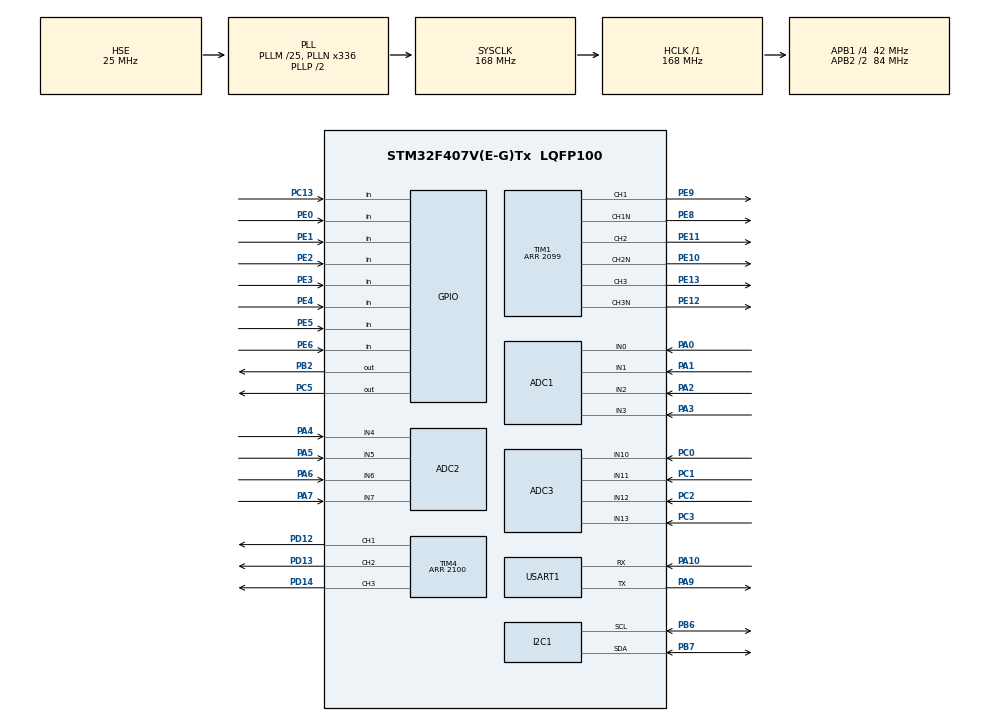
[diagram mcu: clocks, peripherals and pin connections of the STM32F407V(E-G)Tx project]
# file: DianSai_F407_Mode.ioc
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ADC1.Channel-0\#ChannelRegularConversion=ADC_CHANNEL_0
ADC1.NbrOfConversionFlag=1
ADC1.Rank-0\#ChannelRegularConversion=1
ADC1.SamplingTime-0\#ChannelRegularConversion=ADC_SAMPLETIME_3CYCLES
ADC1.master=1
ADC2.Channel-0\#ChannelRegularConversion=ADC_CHANNEL_4
ADC2.NbrOfConversionFlag=1
ADC2.Rank-0\#ChannelRegularConversion=1
ADC2.SamplingTime-0\#ChannelRegularConversion=ADC_SAMPLETIME_3CYCLES
ADC3.Channel-0\#ChannelRegularConversion=ADC_CHANNEL_13
ADC3.NbrOfConversionFlag=1
ADC3.Rank-0\#ChannelRegularConversion=1
ADC3.SamplingTime-0\#ChannelRegularConversion=ADC_SAMPLETIME_3CYCLES
Dma.Request0=USART1_RX
Dma.USART1_RX.0.Direction=DMA_PERIPH_TO_MEMORY
Dma.USART1_RX.0.FIFOMode=DMA_FIFOMODE_DISABLE
Dma.USART1_RX.0.Instance=DMA2_Stream2
Dma.USART1_RX.0.MemDataAlignment=DMA_MDATAALIGN_BYTE
Dma.USART1_RX.0.MemInc=DMA_MINC_ENABLE
Dma.USART1_RX.0.Mode=DMA_NORMAL
Dma.USART1_RX.0.PeriphDataAlignment=DMA_PDATAALIGN_BYTE
Dma.USART1_RX.0.PeriphInc=DMA_PINC_DISABLE
Dma.USART1_RX.0.Priority=DMA_PRIORITY_HIGH
I2C1.I2C_Mode=I2C_Fast
Mcu.Family=STM32F4
Mcu.Name=STM32F407V(E-G)Tx
Mcu.Package=LQFP100
NVIC.DMA2_Stream2_IRQn=true\:0\:0\:false\:false\:true\:false\:true\:true
NVIC.PriorityGroup=NVIC_PRIORITYGROUP_4
NVIC.TIM1_UP_TIM10_IRQn=true\:0\:0\:false\:false\:true\:true\:true\:true
NVIC.TIM4_IRQn=true\:0\:0\:false\:false\:true\:true\:true\:true
NVIC.USART1_IRQn=true\:0\:0\:false\:false\:true\:true\:true\:true
PA0-WKUP.Signal=ADCx_IN0
PA1.Signal=ADCx_IN1
PA10.Mode=Asynchronous
PA10.Signal=USART1_RX
PA2.Signal=ADCx_IN2
PA3.Signal=ADCx_IN3
PA4.Signal=ADCx_IN4
PA5.Signal=ADCx_IN5
PA6.Signal=ADCx_IN6
PA7.Signal=ADCx_IN7
PA9.Mode=Asynchronous
PA9.Signal=USART1_TX
PB2.GPIO_PuPd=GPIO_NOPULL
PB2.PinState=GPIO_PIN_SET
PB2.Signal=GPIO_Output
PB6.Mode=I2C
PB6.Signal=I2C1_SCL
PB7.Mode=I2C
PB7.Signal=I2C1_SDA
PC0.Signal=ADCx_IN10
PC1.Signal=ADCx_IN11
PC13-ANTI_TAMP.GPIO_Mode=GPIO_MODE_INPUT
PC13-ANTI_TAMP.GPIO_PuPd=GPIO_PULLUP
PC13-ANTI_TAMP.Signal=GPIO_Input
PC2.Signal=ADCx_IN12
PC3.Signal=ADCx_IN13
PC5.GPIO_ModeDefaultOutputPP=GPIO_MODE_OUTPUT_PP
PC5.GPIO_PuPd=GPIO_NOPULL
PC5.PinState=GPIO_PIN_SET
PC5.Signal=GPIO_Output
PD0.Signal=CAN1_RX
PD1.Signal=CAN1_TX
PD12.Signal=S_TIM4_CH1
PD13.Signal=S_TIM4_CH2
PD14.Signal=S_TIM4_CH3
PD15.Signal=S_TIM4_CH4
PE0.GPIO_Mode=GPIO_MODE_INPUT
PE0.GPIO_PuPd=GPIO_PULLUP
PE0.Signal=GPIO_Input
PE1.GPIO_Mode=GPIO_MODE_INPUT
PE1.GPIO_PuPd=GPIO_PULLUP
PE1.Signal=GPIO_Input
PE10.Mode=PWM Generation2 CH2 CH2N
PE10.Signal=TIM1_CH2N
PE11.Signal=S_TIM1_CH2
PE12.Mode=PWM Generation3 CH3 CH3N
PE12.Signal=TIM1_CH3N
PE13.Signal=S_TIM1_CH3
PE2.GPIO_Mode=GPIO_MODE_INPUT
PE2.GPIO_PuPd=GPIO_PULLUP
PE2.Signal=GPIO_Input
PE3.GPIO_Mode=GPIO_MODE_INPUT
PE3.GPIO_PuPd=GPIO_PULLUP
PE3.Signal=GPIO_Input
PE4.GPIO_Mode=GPIO_MODE_INPUT
PE4.GPIO_PuPd=GPIO_PULLUP
PE4.Signal=GPIO_Input
PE5.GPIO_Mode=GPIO_MODE_INPUT
PE5.GPIO_PuPd=GPIO_PULLUP
PE5.Signal=GPIO_Input
PE6.GPIO_Mode=GPIO_MODE_INPUT
PE6.GPIO_PuPd=GPIO_PULLUP
PE6.Signal=GPIO_Input
PE8.Mode=PWM Generation1 CH1 CH1N
PE8.Signal=TIM1_CH1N
PE9.Signal=S_TIM1_CH1
PH0-OSC_IN.Mode=HSE-External-Oscillator
PH0-OSC_IN.Signal=RCC_OSC_IN
PH1-OSC_OUT.Mode=HSE-External-Oscillator
PH1-OSC_OUT.Signal=RCC_OSC_OUT
ProjectManager.HeapSize=0x200
ProjectManager.StackSize=0x400
ProjectManager.TargetToolchain=MDK-ARM V5.32
RCC.48MHZClocksFreq_Value=84000000
RCC.AHBFreq_Value=168000000
RCC.APB1CLKDivider=RCC_HCLK_DIV4
RCC.APB1Freq_Value=42000000
RCC.APB1TimFreq_Value=84000000
RCC.APB2CLKDivider=RCC_HCLK_DIV2
RCC.APB2Freq_Value=84000000
RCC.APB2TimFreq_Value=168000000
RCC.CortexFreq_Value=168000000
RCC.HCLKFreq_Value=168000000
RCC.HSE_VALUE=25000000
RCC.HSI_VALUE=16000000
RCC.LSE_VALUE=32768
RCC.PLLM=25
RCC.PLLN=336
RCC.PLLSourceVirtual=RCC_PLLSOURCE_HSE
RCC.SYSCLKFreq_VALUE=168000000
RCC.SYSCLKSource=RCC_SYSCLKSOURCE_PLLCLK
RCC.VCOOutputFreq_Value=336000000
SH.ADCx_IN0.0=ADC1_IN0,IN0
SH.ADCx_IN1.0=ADC1_IN1,IN1
SH.ADCx_IN10.0=ADC3_IN10,IN10
SH.ADCx_IN11.0=ADC3_IN11,IN11
SH.ADCx_IN12.0=ADC3_IN12,IN12
SH.ADCx_IN13.0=ADC3_IN13,IN13
SH.ADCx_IN2.0=ADC1_IN2,IN2
SH.ADCx_IN3.0=ADC1_IN3,IN3
SH.ADCx_IN4.0=ADC2_IN4,IN4
SH.ADCx_IN5.0=ADC2_IN5,IN5
SH.ADCx_IN6.0=ADC2_IN6,IN6
SH.ADCx_IN7.0=ADC2_IN7,IN7
SH.S_TIM1_CH1.0=TIM1_CH1,PWM Generation1 CH1 CH1N
SH.S_TIM1_CH2.0=TIM1_CH2,PWM Generation2 CH2 CH2N
SH.S_TIM1_CH3.0=TIM1_CH3,PWM Generation3 CH3 CH3N
SH.S_TIM4_CH1.0=TIM4_CH1,PWM Generation1 CH1
SH.S_TIM4_CH2.0=TIM4_CH2,PWM Generation2 CH2
SH.S_TIM4_CH3.0=TIM4_CH3,PWM Generation3 CH3
SH.S_TIM4_CH4.0=TIM4_CH4
TIM1.AutoReloadPreload=TIM_AUTORELOAD_PRELOAD_ENABLE
TIM1.AutomaticOutput=TIM_AUTOMATICOUTPUT_ENABLE
TIM1.Channel-PWM\ Generation1\ CH1\ CH1N=TIM_CHANNEL_1
TIM1.Channel-PWM\ Generation2\ CH2\ CH2N=TIM_CHANNEL_2
TIM1.Channel-PWM\ Generation3\ CH3\ CH3N=TIM_CHANNEL_3
TIM1.CounterMode=TIM_COUNTERMODE_CENTERALIGNED1
TIM1.Period=2099
TIM4.AutoReloadPreload=TIM_AUTORELOAD_PRELOAD_ENABLE
TIM4.Channel-PWM\ Generation1\ CH1=TIM_CHANNEL_1
TIM4.Channel-PWM\ Generation2\ CH2=TIM_CHANNEL_2
TIM4.Channel-PWM\ Generation3\ CH3=TIM_CHANNEL_3
TIM4.CounterMode=TIM_COUNTERMODE_CENTERALIGNED1
TIM4.Period=2100
USART1.VirtualMode=VM_ASYNC
VP_TIM1_VS_ClockSourceINT.Mode=Internal
VP_TIM4_VS_ClockSourceINT.Mode=Internal
board=custom

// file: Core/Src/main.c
/* USER CODE BEGIN Header */
/**
  ******************************************************************************
  * @file           : main.c
  * @brief          : Main program body
  ******************************************************************************
  * @attention
  *
  * Copyright (c) 2026 STMicroelectronics.
  * All rights reserved.
  *
  * This software is licensed under terms that can be found in the LICENSE file
  * in the root directory of this software component.
  * If no LICENSE file comes with this software, it is provided AS-IS.
  *
  ******************************************************************************
  */
/* USER CODE END Header */
#include "main.h"
#include "adc.h"
#include "dma.h"
#include "i2c.h"
#include "tim.h"
#include "usart.h"
#include "gpio.h"

/* USER CODE BEGIN Includes */
#include "bsp_system.h"
/* USER CODE END Includes */

void SystemClock_Config(void);

int main(void)
{

  /* MCU Configuration--------------------------------------------------------*/

  /* Reset of all peripherals, Initializes the Flash interface and the Systick. */
  HAL_Init();

  /* Configure the system clock */
  SystemClock_Config();

  /* Initialize all configured peripherals */
  MX_GPIO_Init();
  MX_DMA_Init();
  MX_I2C1_Init();
  MX_USART1_UART_Init();
  MX_ADC1_Init();
  MX_ADC2_Init();
  MX_ADC3_Init();
  MX_TIM1_Init();
  MX_TIM4_Init();
  /* USER CODE BEGIN 2 */
  system_init();

  /* USER CODE END 2 */

  /* Infinite loop */
  while (1)
  {

    /* USER CODE BEGIN 3 */
		scheduler_run();
  }
  /* USER CODE END 3 */
}

void SystemClock_Config(void)
{
  RCC_OscInitTypeDef RCC_OscInitStruct = {0};
  RCC_ClkInitTypeDef RCC_ClkInitStruct = {0};

  /** Configure the main internal regulator output voltage
  */
  __HAL_RCC_PWR_CLK_ENABLE();
  __HAL_PWR_VOLTAGESCALING_CONFIG(PWR_REGULATOR_VOLTAGE_SCALE1);

  /** Initializes the RCC Oscillators according to the specified parameters
  * in the RCC_OscInitTypeDef structure.
  */
  RCC_OscInitStruct.OscillatorType = RCC_OSCILLATORTYPE_HSE;
  RCC_OscInitStruct.HSEState = RCC_HSE_ON;
  RCC_OscInitStruct.PLL.PLLState = RCC_PLL_ON;
  RCC_OscInitStruct.PLL.PLLSource = RCC_PLLSOURCE_HSE;
  RCC_OscInitStruct.PLL.PLLM = 25;
  RCC_OscInitStruct.PLL.PLLN = 336;
  RCC_OscInitStruct.PLL.PLLP = RCC_PLLP_DIV2;
  RCC_OscInitStruct.PLL.PLLQ = 4;
  if (HAL_RCC_OscConfig(&RCC_OscInitStruct) != HAL_OK)
  {
    Error_Handler();
  }

  /** Initializes the CPU, AHB and APB buses clocks
  */
  RCC_ClkInitStruct.ClockType = RCC_CLOCKTYPE_HCLK|RCC_CLOCKTYPE_SYSCLK
                              |RCC_CLOCKTYPE_PCLK1|RCC_CLOCKTYPE_PCLK2;
  RCC_ClkInitStruct.SYSCLKSource = RCC_SYSCLKSOURCE_PLLCLK;
  RCC_ClkInitStruct.AHBCLKDivider = RCC_SYSCLK_DIV1;
  RCC_ClkInitStruct.APB1CLKDivider = RCC_HCLK_DIV4;
  RCC_ClkInitStruct.APB2CLKDivider = RCC_HCLK_DIV2;

  if (HAL_RCC_ClockConfig(&RCC_ClkInitStruct, FLASH_LATENCY_5) != HAL_OK)
  {
    Error_Handler();
  }
}

void Error_Handler(void)
{
  __disable_irq();
  while (1)
  {
  }
}
